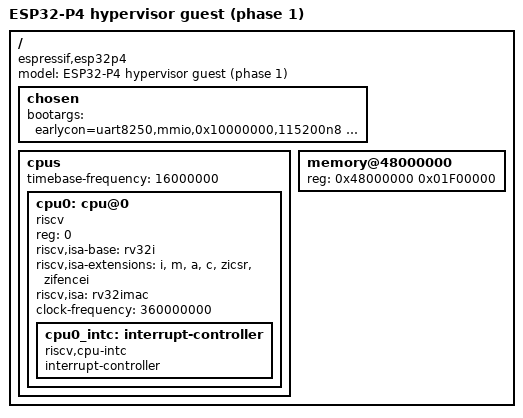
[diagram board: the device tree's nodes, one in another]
/*
 * ESP32-P4 hypervisor guest — PHASE 1
 *
 * Goal: get boot messages out. Nothing else.
 *
 * Describes only memory and one CPU. No timer, no interrupt controller,
 * no console driver. Output happens purely through earlycon, which pokes
 * a fixed address without any driver probing.
 *
 * Expected result: Linux boots as far as "Memory: NNNNK/16384K available"
 * and then HANGS. That hang is correct — there is no timer yet.
 *
 * Traps you must handle for this phase:
 *   - illegal instruction (cause 2): CSR ops, mret, wfi
 *   - store access fault  (cause 7): writes to 0x10000000 -> real UART
 */

/dts-v1/;

/ {
	#address-cells = <1>; 
	#size-cells = <1>;
	compatible = "espressif,esp32p4";
	model = "ESP32-P4 hypervisor guest (phase 1)";

	chosen {
		/*
		 * earlycon=uart8250,mmio,ADDR,BAUD
		 *   mmio  = 8-bit register spacing (matches reg-shift = 0)
		 *   ADDR  = the fake 16550 your monitor emulates
		 *   BAUD  = must be present, and must match the kernel's built-in
		 *           CONFIG_CMDLINE ("...,0x10000000,115200n8"), or the two
		 *           take different paths through early_serial8250_setup:
		 *           with a baud it calls init_port() and writes LCR/IER/
		 *           FCR/MCR, without one it only masks IER. The monitor
		 *           must emulate whichever actually runs.
		 *
		 * No clock is given after the baud, so port->uartclk stays 0 and
		 * the DLAB block is skipped — no DLL/DLM writes to emulate.
		 *
		 * No console= yet: there is no tty driver in this phase, so
		 * keep_bootcon holds earlycon open once handoff is attempted.
		 */
		bootargs = "earlycon=uart8250,mmio,0x10000000,115200n8 keep_bootcon";
	};

	cpus {
		#address-cells = <1>;
		#size-cells = <0>;

		/*
		 * MUST match the rate your emulated mtime actually counts at.
		 * If you back mtime with the P4 SYSTIMER, that is 16 MHz.
		 * Unused in phase 1 (no timer node) but Linux reads it early,
		 * so keep it correct from the start.
		 */
		timebase-frequency = <16000000>;

		cpu0: cpu@0 {
			device_type = "cpu";
			compatible = "riscv";
			reg = <0>;
			status = "okay";

			riscv,isa-base = "rv32i";
			riscv,isa-extensions = "i", "m", "a", "c",
					       "zicsr", "zifencei";

			/* legacy property, some code still reads it */
			riscv,isa = "rv32imac";

			clock-frequency = <360000000>;

			cpu0_intc: interrupt-controller {
				#interrupt-cells = <1>;
				compatible = "riscv,cpu-intc";
				interrupt-controller;
			};
		};
	};

	/*
	 * MUST NOT exceed the PMP grant. Declaring more than the monitor granted
	 * shows up as an access fault that looks like a hypervisor bug but is
	 * really Linux allocating outside its window. Declaring less is fine and
	 * is how the device windows above are kept out of the allocator.
	 */
	memory@48000000 {
		device_type = "memory";
		/*
		 * 31 MB of the 32 MB PSRAM window. The PMP grant covers the full
		 * 32 MB (0x48000000-0x4A000000); the top 1 MB is deliberately left
		 * out of this node so Linux will not allocate over the DTB at
		 * 0x49F00000 or the device windows placed above it.
		 */
		reg = <0x48000000 0x01F00000>;
	};
};
